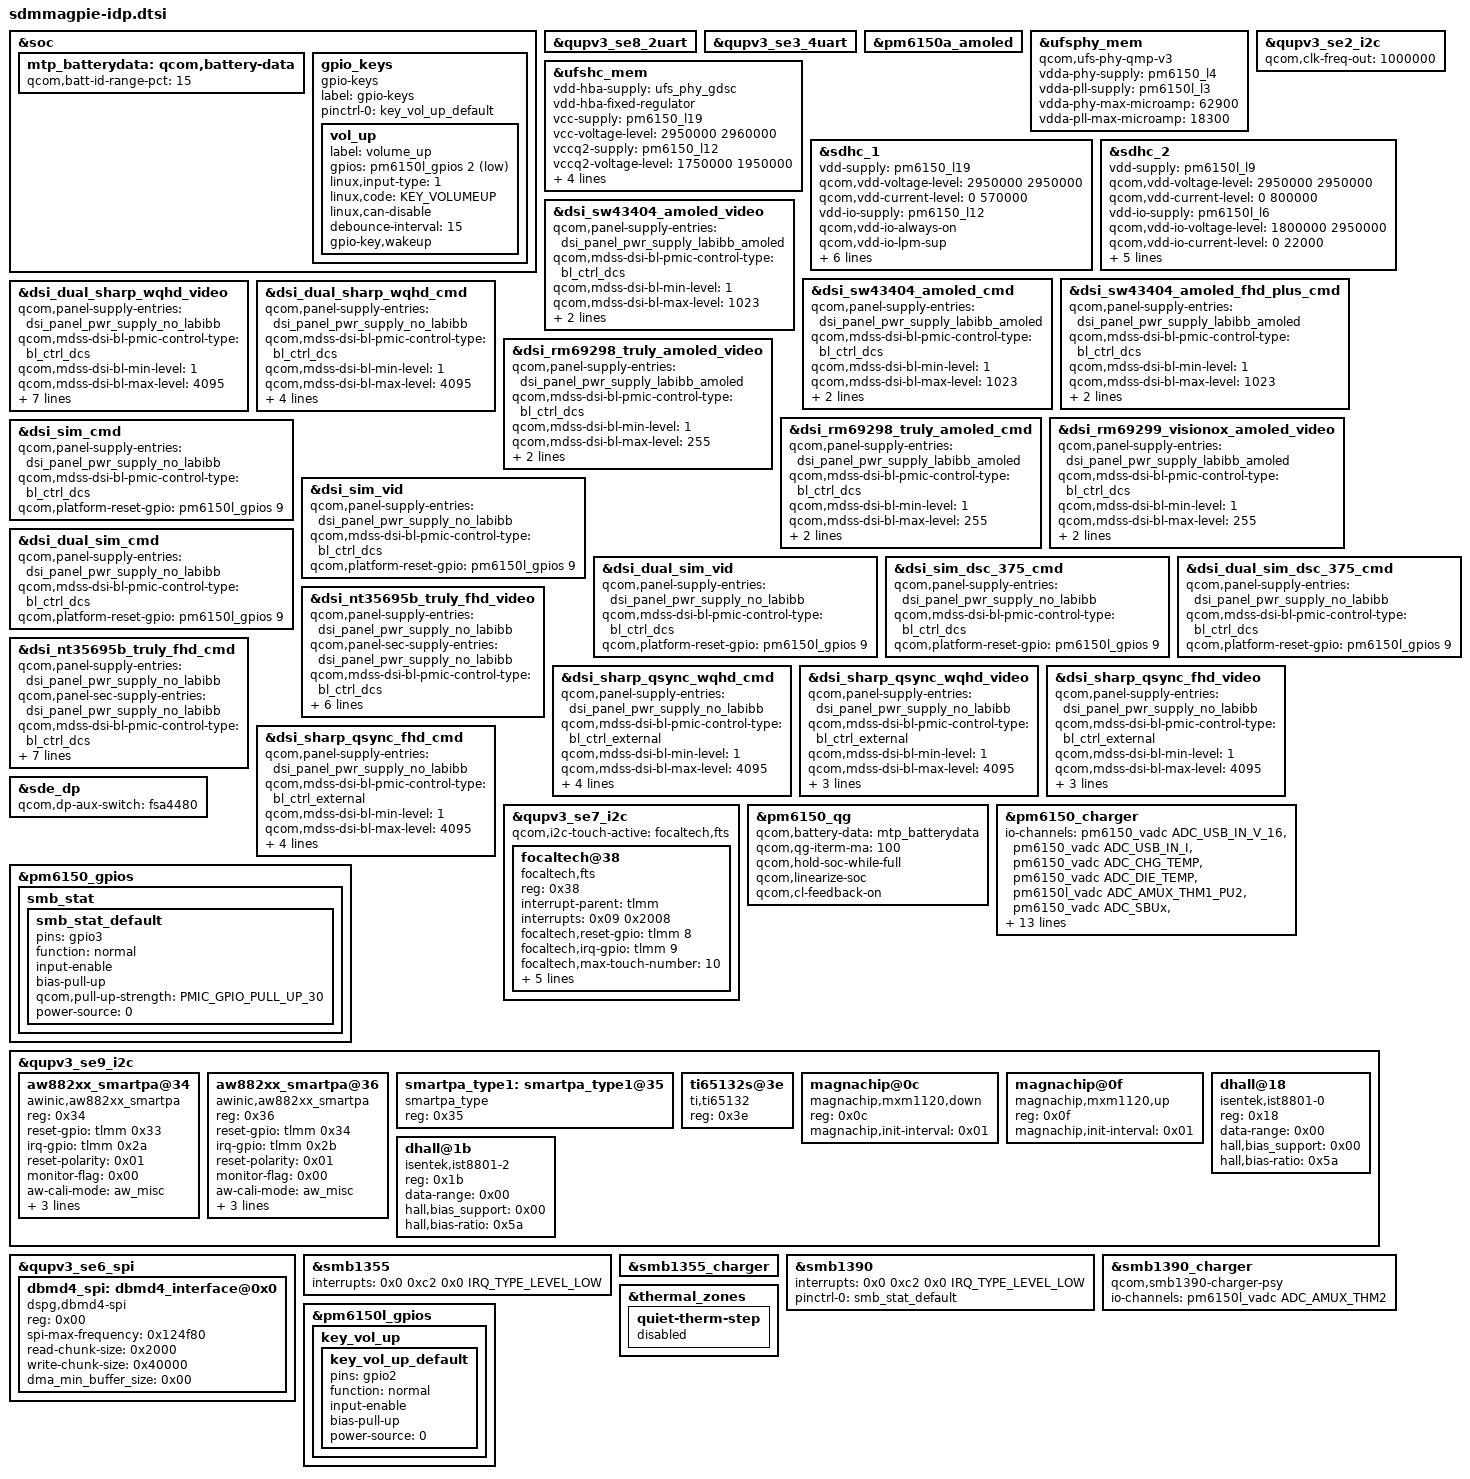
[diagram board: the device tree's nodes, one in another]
/* Copyright (c) 2018-2019, The Linux Foundation. All rights reserved.
 *
 * This program is free software; you can redistribute it and/or modify
 * it under the terms of the GNU General Public License version 2 and
 * only version 2 as published by the Free Software Foundation.
 *
 * This program is distributed in the hope that it will be useful,
 * but WITHOUT ANY WARRANTY; without even the implied warranty of
 * MERCHANTABILITY or FITNESS FOR A PARTICULAR PURPOSE.  See the
 * GNU General Public License for more details.
 */
#include "sdmmagpie-thermal-overlay.dtsi"

#include <dt-bindings/gpio/gpio.h>
#include <dt-bindings/pinctrl/qcom,pmic-gpio.h>
#include <dt-bindings/iio/qcom,spmi-vadc.h>
#include <dt-bindings/input/input.h>
#include "sdmmagpie-sde-display.dtsi"
#include "sdmmagpie-camera-sensor-idp.dtsi"

&soc {
	mtp_batterydata: qcom,battery-data {
		qcom,batt-id-range-pct = <15>;
		// BBK_VENDOR_EDIT
		//#include "qg-batterydata-alium-3600mah.dtsi"
		//#include "qg-batterydata-mlp466076-3200mah.dtsi"
		#include "qg-batterydata-3864045_BBK_ATL_8020mAH_PM7150.dtsi"
		#include "qg-batterydata-5806736_BBK_ATL2_8020mAH_PM7150.dtsi"
		#include "qg-batterydata-3864045_BBK_GY_8020mAH_PM7150.dtsi"
	};
};

&qupv3_se8_2uart {
	status = "ok";
};

&qupv3_se3_4uart {
	status = "ok";
};

&pm6150a_amoled {
	status = "ok";
};

&ufsphy_mem {
	compatible = "qcom,ufs-phy-qmp-v3";

	vdda-phy-supply = <&pm6150_l4>; /* 0.88v */
	vdda-pll-supply = <&pm6150l_l3>; /* 1.2v */
	vdda-phy-max-microamp = <62900>;
	vdda-pll-max-microamp = <18300>;

	status = "ok";
};

&ufshc_mem {
	vdd-hba-supply = <&ufs_phy_gdsc>;
	vdd-hba-fixed-regulator;
	vcc-supply = <&pm6150_l19>;
	vcc-voltage-level = <2950000 2960000>;
	vccq2-supply = <&pm6150_l12>;
	vccq2-voltage-level = <1750000 1950000>;
	vcc-max-microamp = <600000>;
	vccq2-max-microamp = <600000>;

	qcom,vddp-ref-clk-supply = <&pm6150l_l3>;
	qcom,vddp-ref-clk-max-microamp = <100>;

	status = "ok";
};

&qupv3_se2_i2c {
	status = "ok";
	qcom,clk-freq-out = <1000000>;
	// BBK_VENDOR_EDIT
	/*nq@28 {
		compatible = "qcom,nq-nci";
		reg = <0x28>;
		qcom,nq-irq = <&tlmm 37 0x00>;
		qcom,nq-ven = <&tlmm 12 0x00>;
		qcom,nq-firm = <&tlmm 36 0x00>;
		qcom,nq-clkreq = <&tlmm 31 0x00>;
		qcom,nq-esepwr = <&tlmm 94 0x00>;
		interrupt-parent = <&tlmm>;
		interrupts = <37 0>;
		interrupt-names = "nfc_irq";
		pinctrl-names = "nfc_active", "nfc_suspend";
		pinctrl-0 = <&nfc_int_active &nfc_enable_active
				&nfc_clk_req_active>;
		pinctrl-1 = <&nfc_int_suspend &nfc_enable_suspend
				&nfc_clk_req_suspend>;
	};*/
};

&sdhc_1 {
	vdd-supply = <&pm6150_l19>;
	qcom,vdd-voltage-level = <2950000 2950000>;
	qcom,vdd-current-level = <0 570000>;

	vdd-io-supply = <&pm6150_l12>;
	qcom,vdd-io-always-on;
	qcom,vdd-io-lpm-sup;
	qcom,vdd-io-voltage-level = <1800000 1800000>;
	qcom,vdd-io-current-level = <0 325000>;

	pinctrl-names = "active", "sleep";
	pinctrl-0 = <&sdc1_clk_on &sdc1_cmd_on &sdc1_data_on &sdc1_rclk_on>;
	pinctrl-1 = <&sdc1_clk_off &sdc1_cmd_off &sdc1_data_off &sdc1_rclk_off>;

	status = "ok";
};

&sdhc_2 {
	vdd-supply = <&pm6150l_l9>;
	qcom,vdd-voltage-level = <2950000 2950000>;
	qcom,vdd-current-level = <0 800000>;

	vdd-io-supply = <&pm6150l_l6>;
	qcom,vdd-io-voltage-level = <1800000 2950000>;
	qcom,vdd-io-current-level = <0 22000>;

	pinctrl-names = "active", "sleep";
	pinctrl-0 = <&sdc2_clk_on  &sdc2_cmd_on &sdc2_data_on &sdc2_cd_on>;
	pinctrl-1 = <&sdc2_clk_off &sdc2_cmd_off &sdc2_data_off &sdc2_cd_off>;

	cd-gpios = <&tlmm 69 GPIO_ACTIVE_LOW>;

	status = "ok";
};

&dsi_sw43404_amoled_video {
	qcom,panel-supply-entries = <&dsi_panel_pwr_supply_labibb_amoled>;
	qcom,mdss-dsi-bl-pmic-control-type = "bl_ctrl_dcs";
	qcom,mdss-dsi-bl-min-level = <1>;
	qcom,mdss-dsi-bl-max-level = <1023>;
	qcom,platform-te-gpio = <&tlmm 10 0>;
	qcom,platform-reset-gpio = <&pm6150l_gpios 9 0>;
};

&dsi_sw43404_amoled_cmd {
	qcom,panel-supply-entries = <&dsi_panel_pwr_supply_labibb_amoled>;
	qcom,mdss-dsi-bl-pmic-control-type = "bl_ctrl_dcs";
	qcom,mdss-dsi-bl-min-level = <1>;
	qcom,mdss-dsi-bl-max-level = <1023>;
	qcom,platform-te-gpio = <&tlmm 10 0>;
	qcom,platform-reset-gpio = <&pm6150l_gpios 9 0>;
};

&dsi_sw43404_amoled_fhd_plus_cmd {
	qcom,panel-supply-entries = <&dsi_panel_pwr_supply_labibb_amoled>;
	qcom,mdss-dsi-bl-pmic-control-type = "bl_ctrl_dcs";
	qcom,mdss-dsi-bl-min-level = <1>;
	qcom,mdss-dsi-bl-max-level = <1023>;
	qcom,platform-te-gpio = <&tlmm 10 0>;
	qcom,platform-reset-gpio = <&pm6150l_gpios 9 0>;
};

&dsi_dual_sharp_wqhd_video {
	qcom,panel-supply-entries = <&dsi_panel_pwr_supply_no_labibb>;
	qcom,mdss-dsi-bl-pmic-control-type = "bl_ctrl_dcs";
	qcom,mdss-dsi-bl-min-level = <1>;
	qcom,mdss-dsi-bl-max-level = <4095>;
	qcom,platform-te-gpio = <&tlmm 10 0>;
	qcom,platform-reset-gpio = <&pm6150l_gpios 9 0>;
	qcom,platform-en-gpio = <&pm6150l_gpios 4 0>;
	qcom,platform-bklight-en-gpio = <&pm6150l_gpios 5 0>;
	qcom,platform-enp-gpio = <&tlmm 0x40 0x00>;
	qcom,platform-enn-gpio = <&tlmm 0x41 0x00>;
	pwms = <&pm6150l_pwm_1 0x01 0x00>;
};

&dsi_dual_sharp_wqhd_cmd {
	qcom,panel-supply-entries = <&dsi_panel_pwr_supply_no_labibb>;
	qcom,mdss-dsi-bl-pmic-control-type = "bl_ctrl_dcs";
	qcom,mdss-dsi-bl-min-level = <1>;
	qcom,mdss-dsi-bl-max-level = <4095>;
	qcom,platform-te-gpio = <&tlmm 10 0>;
	qcom,platform-reset-gpio = <&pm6150l_gpios 9 0>;
	qcom,platform-en-gpio = <&pm6150l_gpios 4 0>;
	qcom,platform-bklight-en-gpio = <&pm6150l_gpios 5 0>;
};

&dsi_rm69298_truly_amoled_video {
	qcom,panel-supply-entries = <&dsi_panel_pwr_supply_labibb_amoled>;
	qcom,mdss-dsi-bl-pmic-control-type = "bl_ctrl_dcs";
	qcom,mdss-dsi-bl-min-level = <1>;
	qcom,mdss-dsi-bl-max-level = <255>;
	qcom,platform-te-gpio = <&tlmm 10 0>;
	qcom,platform-reset-gpio = <&pm6150l_gpios 9 0>;
};

&dsi_rm69298_truly_amoled_cmd {
	qcom,panel-supply-entries = <&dsi_panel_pwr_supply_labibb_amoled>;
	qcom,mdss-dsi-bl-pmic-control-type = "bl_ctrl_dcs";
	qcom,mdss-dsi-bl-min-level = <1>;
	qcom,mdss-dsi-bl-max-level = <255>;
	qcom,platform-te-gpio = <&tlmm 10 0>;
	qcom,platform-reset-gpio = <&pm6150l_gpios 9 0>;
};

&dsi_rm69299_visionox_amoled_video {
	qcom,panel-supply-entries = <&dsi_panel_pwr_supply_labibb_amoled>;
	qcom,mdss-dsi-bl-pmic-control-type = "bl_ctrl_dcs";
	qcom,mdss-dsi-bl-min-level = <1>;
	qcom,mdss-dsi-bl-max-level = <255>;
	qcom,platform-te-gpio = <&tlmm 10 0>;
	qcom,platform-reset-gpio = <&pm6150l_gpios 9 0>;
};

&dsi_sim_cmd {
	qcom,panel-supply-entries = <&dsi_panel_pwr_supply_no_labibb>;
	qcom,mdss-dsi-bl-pmic-control-type = "bl_ctrl_dcs";
	qcom,platform-reset-gpio = <&pm6150l_gpios 9 0>;
};

&dsi_sim_vid {
	qcom,panel-supply-entries = <&dsi_panel_pwr_supply_no_labibb>;
	qcom,mdss-dsi-bl-pmic-control-type = "bl_ctrl_dcs";
	qcom,platform-reset-gpio = <&pm6150l_gpios 9 0>;
};

&dsi_dual_sim_cmd {
	qcom,panel-supply-entries = <&dsi_panel_pwr_supply_no_labibb>;
	qcom,mdss-dsi-bl-pmic-control-type = "bl_ctrl_dcs";
	qcom,platform-reset-gpio = <&pm6150l_gpios 9 0>;
};

&dsi_dual_sim_vid {
	qcom,panel-supply-entries = <&dsi_panel_pwr_supply_no_labibb>;
	qcom,mdss-dsi-bl-pmic-control-type = "bl_ctrl_dcs";
	qcom,platform-reset-gpio = <&pm6150l_gpios 9 0>;
};

&dsi_sim_dsc_375_cmd {
	qcom,panel-supply-entries = <&dsi_panel_pwr_supply_no_labibb>;
	qcom,mdss-dsi-bl-pmic-control-type = "bl_ctrl_dcs";
	qcom,platform-reset-gpio = <&pm6150l_gpios 9 0>;
};

&dsi_dual_sim_dsc_375_cmd {
	qcom,panel-supply-entries = <&dsi_panel_pwr_supply_no_labibb>;
	qcom,mdss-dsi-bl-pmic-control-type = "bl_ctrl_dcs";
	qcom,platform-reset-gpio = <&pm6150l_gpios 9 0>;
};

&dsi_nt35695b_truly_fhd_video {
	qcom,panel-supply-entries = <&dsi_panel_pwr_supply_no_labibb>;
	qcom,panel-sec-supply-entries = <&dsi_panel_pwr_supply_no_labibb>;
	qcom,mdss-dsi-bl-pmic-control-type = "bl_ctrl_dcs";
	qcom,mdss-dsi-sec-bl-pmic-control-type = "bl_ctrl_dcs";
	qcom,platform-reset-gpio = <&pm6150l_gpios 11 0>;
	qcom,platform-sec-reset-gpio = <&pm6150l_gpios 11 0>;
	qcom,platform-en-gpio = <&pm6150l_gpios 4 0>;
	qcom,platform-bklight-en-gpio = <&pm6150l_gpios 5 0>;
};

&dsi_nt35695b_truly_fhd_cmd {
	qcom,panel-supply-entries = <&dsi_panel_pwr_supply_no_labibb>;
	qcom,panel-sec-supply-entries = <&dsi_panel_pwr_supply_no_labibb>;
	qcom,mdss-dsi-bl-pmic-control-type = "bl_ctrl_dcs";
	qcom,mdss-dsi-sec-bl-pmic-control-type = "bl_ctrl_dcs";
	qcom,platform-reset-gpio = <&pm6150l_gpios 11 0>;
	qcom,platform-sec-reset-gpio = <&pm6150l_gpios 11 0>;
	qcom,platform-en-gpio = <&pm6150l_gpios 4 0>;
	qcom,platform-bklight-en-gpio = <&pm6150l_gpios 5 0>;
	qcom,platform-te-gpio = <&tlmm 11 0>;
};

&dsi_sharp_qsync_wqhd_cmd {
	qcom,panel-supply-entries = <&dsi_panel_pwr_supply_no_labibb>;
	qcom,mdss-dsi-bl-pmic-control-type = "bl_ctrl_external";
	qcom,mdss-dsi-bl-min-level = <1>;
	qcom,mdss-dsi-bl-max-level = <4095>;
	qcom,platform-te-gpio = <&tlmm 10 0>;
	qcom,platform-reset-gpio = <&pm6150l_gpios 9 0>;
	qcom,platform-en-gpio = <&pm6150l_gpios 4 0>;
	qcom,platform-bklight-en-gpio = <&pm6150l_gpios 5 0>;
};

&dsi_sharp_qsync_wqhd_video {
	qcom,panel-supply-entries = <&dsi_panel_pwr_supply_no_labibb>;
	qcom,mdss-dsi-bl-pmic-control-type = "bl_ctrl_external";
	qcom,mdss-dsi-bl-min-level = <1>;
	qcom,mdss-dsi-bl-max-level = <4095>;
	qcom,platform-reset-gpio = <&pm6150l_gpios 9 0>;
	qcom,platform-en-gpio = <&pm6150l_gpios 4 0>;
	qcom,platform-bklight-en-gpio = <&pm6150l_gpios 5 0>;
};

&dsi_sharp_qsync_fhd_video {
	qcom,panel-supply-entries = <&dsi_panel_pwr_supply_no_labibb>;
	qcom,mdss-dsi-bl-pmic-control-type = "bl_ctrl_external";
	qcom,mdss-dsi-bl-min-level = <1>;
	qcom,mdss-dsi-bl-max-level = <4095>;
	qcom,platform-reset-gpio = <&pm6150l_gpios 9 0>;
	qcom,platform-en-gpio = <&pm6150l_gpios 4 0>;
	qcom,platform-bklight-en-gpio = <&pm6150l_gpios 5 0>;
};

&dsi_sharp_qsync_fhd_cmd {
	qcom,panel-supply-entries = <&dsi_panel_pwr_supply_no_labibb>;
	qcom,mdss-dsi-bl-pmic-control-type = "bl_ctrl_external";
	qcom,mdss-dsi-bl-min-level = <1>;
	qcom,mdss-dsi-bl-max-level = <4095>;
	qcom,platform-te-gpio = <&tlmm 10 0>;
	qcom,platform-reset-gpio = <&pm6150l_gpios 9 0>;
	qcom,platform-en-gpio = <&pm6150l_gpios 4 0>;
	qcom,platform-bklight-en-gpio = <&pm6150l_gpios 5 0>;
};

&sde_dp {
	qcom,dp-aux-switch = <&fsa4480>;
};

&qupv3_se7_i2c {
// BBK_VENDOR_EDIT FocalTech FT8201AB
	qcom,i2c-touch-active="focaltech,fts";
	// BBK_VENDOR_EDIT
	status = "ok";
// BBK_VENDOR_EDIT
	/*st_fts@49 {
		compatible = "st,fts";
		reg = <0x49>;
		interrupt-parent = <&tlmm>;
		interrupts = <9 0x2008>;
		vdd-supply = <&pm6150_l10>;
		avdd-supply = <&pm6150l_l7>;
		pinctrl-names = "pmx_ts_active", "pmx_ts_suspend",
					"pmx_ts_release";
		pinctrl-0 = <&ts_active>;
		pinctrl-1 = <&ts_int_suspend &ts_reset_suspend>;
		pinctrl-2 = <&ts_release>;
		st,irq-gpio = <&tlmm 9 0x2008>;
		st,reset-gpio = <&tlmm 8 0x00>;
		st,regulator_dvdd = "vdd";
		st,regulator_avdd = "avdd";
		st,x-flip;
		st,y-flip;
	};

	synaptics_dsx@20 {
		compatible = "synaptics,dsx-i2c";
		reg = <0x20>;
		interrupt-parent = <&tlmm>;
		interrupts = <9 0x2008>;
		vdd-supply = <&pm6150_l10>;
		avdd-supply = <&pm6150l_l7>;
		pinctrl-names = "pmx_ts_active","pmx_ts_suspend",
					"pmx_ts_release";
		pinctrl-0 = <&ts_active>;
		pinctrl-1 = <&ts_int_suspend &ts_reset_suspend>;
		pinctrl-2 = <&ts_release>;
		synaptics,pwr-reg-name = "avdd";
		synaptics,bus-reg-name = "vdd";
		synaptics,ub-i2c-addr = <0x20>;
		synaptics,max-y-for-2d = <2159>;
		synaptics,irq-gpio = <&tlmm 9 0x2008>;
		synaptics,reset-gpio = <&tlmm 8 0x0>;
		synaptics,irq-on-state = <0>;
		synaptics,power-delay-ms = <200>;
		synaptics,reset-delay-ms = <200>;
		synaptics,reset-on-state = <0>;
		synaptics,reset-active-ms = <20>;
	};*/
	
	focaltech@38 {
		compatible = "focaltech,fts";
		reg = <0x38>;
		interrupt-parent = <&tlmm>;
		interrupts = <0x09 0x2008>;
		focaltech,reset-gpio = <&tlmm 8 0x00>;
		focaltech,irq-gpio = <&tlmm 9 0x2008>;
		focaltech,max-touch-number = <10>;
		focaltech,display-coords = <0x00 0x00 0x63f 0x87f>;
		pinctrl-names = "pmx_ts_active","pmx_ts_suspend","pmx_ts_release";
		pinctrl-0 = <&ts_active>;
		pinctrl-1 = <&ts_int_suspend &ts_reset_suspend>;
		pinctrl-2 = <&ts_release>;
	};
	// BBK_VENDOR_EDIT
};

&pm6150_qg {
	qcom,battery-data = <&mtp_batterydata>;
	qcom,qg-iterm-ma = <100>;
	qcom,hold-soc-while-full;
	qcom,linearize-soc;
	qcom,cl-feedback-on;
};

&pm6150_charger {
	io-channels = <&pm6150_vadc ADC_USB_IN_V_16>,
		      <&pm6150_vadc ADC_USB_IN_I>,
		      <&pm6150_vadc ADC_CHG_TEMP>,
		      <&pm6150_vadc ADC_DIE_TEMP>,
		      <&pm6150l_vadc ADC_AMUX_THM1_PU2>,
		      <&pm6150_vadc ADC_SBUx>,
		      <&pm6150_vadc ADC_VPH_PWR>;
	io-channel-names = "usb_in_voltage",
			   "usb_in_current",
			   "chg_temp",
			   "die_temp",
			   "conn_temp",
			   "sbux_res",
			   "vph_voltage";
	qcom,battery-data = <&mtp_batterydata>;
	qcom,auto-recharge-soc = <98>;
	qcom,step-charging-enable;
	qcom,sw-jeita-enable;
	qcom,fcc-stepping-enable;
	qcom,suspend-input-on-debug-batt;
	qcom,sec-charger-config = <3>;
	qcom,thermal-mitigation = <4200000 3500000 3000000
			2500000 2000000 1500000 1000000 500000>;
	dpdm-supply = <&qusb_phy0>;
	qcom,charger-temp-max = <800>;
	qcom,smb-temp-max = <800>;
};

&pm6150_gpios {
	smb_stat {
		smb_stat_default: smb_stat_default {
			pins = "gpio3";
			function = "normal";
			input-enable;
			bias-pull-up;
			qcom,pull-up-strength = <PMIC_GPIO_PULL_UP_30>;
			power-source = <0>;
		};
	};
};

&qupv3_se9_i2c {
	status = "ok";
	#include "smb1390.dtsi"
	#include "smb1355.dtsi"
			
	// BBK_VENDOR_EDIT
	aw882xx_smartpa@34 {
		compatible = "awinic,aw882xx_smartpa";
		reg = <0x34>;
		reset-gpio = <&tlmm 0x33 0x00>;
		irq-gpio = <&tlmm 0x2a 0x2008>;
		reset-polarity = <0x01>;
		monitor-flag = <0x00>;
		aw-cali-mode = "aw_misc";
		sound-channel = "left";
		aw-stereo-cali;
		monitor-timer-val = <0xbb8>;
		status = "okay";
	};

	aw882xx_smartpa@36 {
		compatible = "awinic,aw882xx_smartpa";
		reg = <0x36>;
		reset-gpio = <&tlmm 0x34 0x00>;
		irq-gpio = <&tlmm 0x2b 0x2008>;
		reset-polarity = <0x01>;
		monitor-flag = <0x00>;
		aw-cali-mode = "aw_misc";
		sound-channel = "right";
		aw-stereo-cali;
		monitor-timer-val = <0xbb8>;
		status = "okay";
	};

	smartpa_type1: smartpa_type1@35 {
		compatible = "smartpa_type";
		reg = <0x35>;
		status = "okay";
	};
	
	ti65132s@3e {
		compatible = "ti,ti65132";
		reg = <0x3e>;
	};

	magnachip@0c {
		compatible = "magnachip,mxm1120,down";
		reg = <0x0c>;
		magnachip,init-interval = <0x01>;
	};

	magnachip@0f {
		compatible = "magnachip,mxm1120,up";
		reg = <0x0f>;
		magnachip,init-interval = <0x01>;
	};

	dhall@18 {
		status = "okay";
		compatible = "isentek,ist8801-0";
		reg = <0x18>;
		data-range = <0x00>;
		hall,bias_support = <0x00>;
		hall,bias-ratio = <0x5a>;
	};

	dhall@1b {
		status = "okay";
		compatible = "isentek,ist8801-2";
		reg = <0x1b>;
		data-range = <0x00>;
		hall,bias_support = <0x00>;
		hall,bias-ratio = <0x5a>;
	};
	// BBK_VENDOR_EDIT
};

// BBK_VENDOR_EDIT
&qupv3_se6_spi {

	dbmd4_spi: dbmd4_interface@0x0 {
		compatible = "dspg,dbmd4-spi";
		reg = <0x00>;
		spi-max-frequency = <0x124f80>;
		read-chunk-size = <0x2000>;
		write-chunk-size = <0x40000>;
		dma_min_buffer_size = <0x00>;
	};
};


&smb1355 {
	/delete-property/ interrupts;
	interrupts = <0x0 0xc2 0x0 IRQ_TYPE_LEVEL_LOW>;
	status = "ok";
};

&smb1355_charger {
	status = "ok";
};

&smb1390 {
	/delete-property/ interrupts;
	interrupts = <0x0 0xc2 0x0 IRQ_TYPE_LEVEL_LOW>;
	pinctrl-names = "default";
	pinctrl-0 = <&smb_stat_default>;
	status = "ok";
};

&smb1390_charger {
	compatible = "qcom,smb1390-charger-psy";
	io-channels = <&pm6150l_vadc ADC_AMUX_THM2>;
	io-channel-names = "cp_die_temp";
	status = "ok";
};

&pm6150l_gpios {
	key_vol_up {
		key_vol_up_default: key_vol_up_default {
			pins = "gpio2";
			function = "normal";
			input-enable;
			bias-pull-up;
			power-source = <0>;
		};
	};
};

&soc {
	gpio_keys {
		compatible = "gpio-keys";
		label = "gpio-keys";

		pinctrl-names = "default";
		pinctrl-0 = <&key_vol_up_default>;

		vol_up {
			label = "volume_up";
			gpios = <&pm6150l_gpios 2 GPIO_ACTIVE_LOW>;
			linux,input-type = <1>;
			linux,code = <KEY_VOLUMEUP>;
			linux,can-disable;
			debounce-interval = <15>;
			gpio-key,wakeup;
		};
	};
};

&thermal_zones {
	quiet-therm-step {
		status = "disabled";
	};
};
